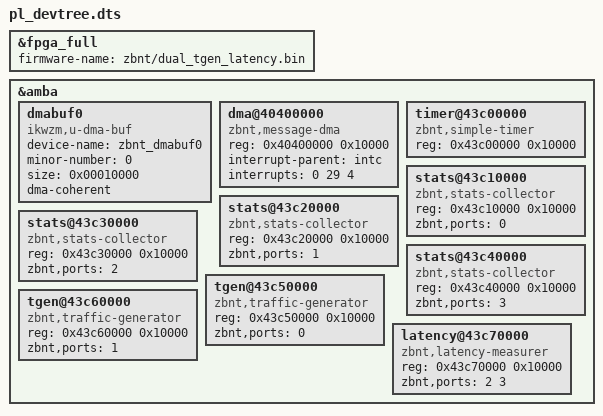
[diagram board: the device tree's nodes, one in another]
/*
	This Source Code Form is subject to the terms of the Mozilla Public
	License, v. 2.0. If a copy of the MPL was not distributed with this
	file, You can obtain one at https://mozilla.org/MPL/2.0/.
*/

/dts-v1/;
/plugin/;

/ {
	fragment@0 {
		target = <&fpga_full>;

		__overlay__ {
			firmware-name = "zbnt/dual_tgen_latency.bin";
		};
	};

	fragment@1 {
		target = <&amba>;

		__overlay__ {
			#address-cells = <1>;
			#size-cells = <1>;

			dmabuf0 {
				compatible = "ikwzm,u-dma-buf";
				device-name = "zbnt_dmabuf0";
				minor-number = <0>;
				size = <0x00010000>;
				dma-coherent;
			};

			dma@40400000 {
				compatible = "zbnt,message-dma", "generic-uio";
				reg = <0x40400000 0x10000>;

				interrupt-names = "irq0";
				interrupt-parent = <&intc>;
				interrupts = <0 29 4>;
			};

			timer@43c00000 {
				compatible = "zbnt,simple-timer", "generic-uio";
				reg = <0x43c00000 0x10000>;
			};

			stats@43c10000 {
				compatible = "zbnt,stats-collector", "generic-uio";
				reg = <0x43c10000 0x10000>;

				zbnt,ports = <0>;
			};

			stats@43c20000 {
				compatible = "zbnt,stats-collector", "generic-uio";
				reg = <0x43c20000 0x10000>;

				zbnt,ports = <1>;
			};

			stats@43c30000 {
				compatible = "zbnt,stats-collector", "generic-uio";
				reg = <0x43c30000 0x10000>;

				zbnt,ports = <2>;
			};

			stats@43c40000 {
				compatible = "zbnt,stats-collector", "generic-uio";
				reg = <0x43c40000 0x10000>;

				zbnt,ports = <3>;
			};

			tgen@43c50000 {
				compatible = "zbnt,traffic-generator", "generic-uio";
				reg = <0x43c50000 0x10000>;

				zbnt,ports = <0>;
			};

			tgen@43c60000 {
				compatible = "zbnt,traffic-generator", "generic-uio";
				reg = <0x43c60000 0x10000>;

				zbnt,ports = <1>;
			};

			latency@43c70000 {
				compatible = "zbnt,latency-measurer", "generic-uio";
				reg = <0x43c70000 0x10000>;

				zbnt,ports = <2 3>;
			};
		};
	};
};
